# PIC32MZ0512EFF144 device description
Architecture: 32xxxx; Family: PIC32MZEF; Series: PIC32MZ
Registers are 32-bit, read-write, no defined reset value unless marked. A register's access mark holds for its fields unless they carry their own. Offsets are from the block's base; [hi:lo] are bit positions; {n}, {i} and the like mark numbered series.

## NVM
Instances: NVM 0x1f800600 in periph_pb1_std
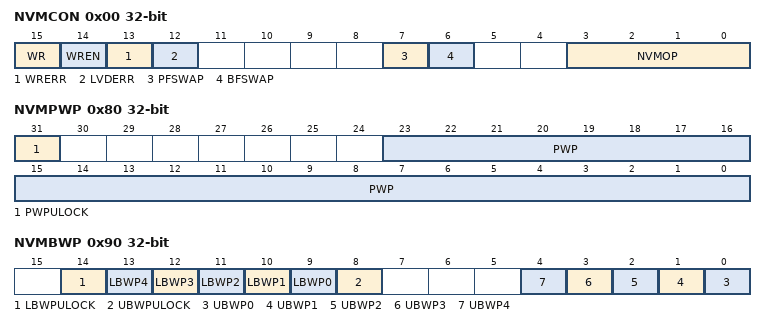
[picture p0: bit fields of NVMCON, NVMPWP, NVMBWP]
0x00 NVMCON — Flash Programming Control Register
  [15] WR — Write Control bit
    1=Initiate a Flash operation; 0=Flash operation is complete or inactive
  [14] WREN — Write Enable bit
    1=Enable writes to the WR bit and disables writes to the NVMOP bits; 0=Disable writes to WR bit and enables writes to the NVMOP bits
  [13] WRERR — Write Error bit
    1=Program or erase sequence did not complete successfully; 0=Program or erase sequence completed normally
  [12] LVDERR — Low-Voltage Detect Error bit
    1=Low-voltage detected (possible data corruption; 0=Voltage level is acceptable for programming
  [7] PFSWAP — Program Flash Bank Swap Control bit
    1=Program Flash Bank 2 is mapped to the lower mapped region and program Flash Bank 1 is mapped to the upper mapped region; 0=Program Flash Bank 1 is mapped to the lower mapped region and program Flash Bank 2 is mapped to the upper mapped region
  [6] BFSWAP — Boot Flash Bank Alias Swap Control bit
    1=Boot Flash Bank 2 is mapped to the lower boot alias and boot Flash Bank 1 is mapped to the upper boot alias; 0=Boot Flash Bank 1 is mapped to the lower boot alias and boot Flash Bank 2 is mapped to the upper boot alias
  [3:0] NVMOP — NVM Operation bits
    3=Program erase operation: erase all of program Flash memory (all pages must be unprotected; 6=Upper program Flash memory erase operation: erases only the upper mapped region of program Flash (all pages in that region must be unprotected); 5=Lower program Flash memory erase operation: erases only the lower mapped region of program Flash (all pages in that region must be unprotected); 4=Page erase operation: erases page selected by NVMADDR; 3=Row program operation: programs row selected by NVMADDR; 2=Quad Word (128-bit) program operation: programs the 128-bit Flash word selected by NVMADDR; 1=Word program operation: programs word selected by NVMADDR; 0=No operation
0x10 NVMKEY wo — Programming Unlock Register
0x20 NVMADDR — Flash Address Register
{0x30+0x10*i} NVMDATA{i} (i=0..3) — Flash Data Register (x = 0-3
0x70 NVMSRCADDR — Source Data Address Register
0x80 NVMPWP — Program Flash Write-Protect Register
  [31] PWPULOCK — Program Flash Memory Page Write-protect Unlock bit
    1=Register is not locked and can be modified; 0=Register is locked and cannot be modified
  [23:0] PWP
0x90 NVMBWP — Flash Boot (Page) Write-Protect Register
  [14] LBWPULOCK — Lower Boot Alias Write-protect Unlock bit
    2=LBWPx bits are not locked and can be modified; 0=LBWPx bits are locked and cannot be modified
  [n+9] LBWP{n} (n=0..4) — Lower Boot Alias Page {n} Write-protect bit
    0=Write protection for physical address {0x1FC00000+0x4000*n} through {0x1FC03FFF+0x4000*n} enabled; 0=Write protection for physical address {0x1FC00000+0x4000*n} through {0x1FC03FFF+0x4000*n} disabled
  [8] UBWPULOCK — Upper Boot Alias Write-protect Unlock bit
    0=UBWPx bits are not locked and can be modified; 0=UBWPx bits are locked and cannot be modified
  [n] UBWP{n} (n=0..4) — Upper Boot Alias Page {n} Write-protect bit
    1=Write protection for physical address {0x1FC20000+0x4000*n} through {0x1FC23FFF+0x4000*n} enabled; 0=Write protection for physical address {0x1FC20000+0x4000*n} through {0x1FC23FFF+0x4000*n} disabled
0xA0 NVMCON2 — Flash Programming Control Register 2
  [7:6] SWAPLOCK — Flash Memory Swap Lock Control bits
    3=PFSWAP and BFSWAP are not writable and SWAPLOCK is not writable; 2=PFSWAP and BFSWAP are not writable and SWAPLOCK is writable; 1=PFSWAP and BFSWAP are not writable and SWAPLOCK is writable; 0=PFSWAP and BFSWAP are writable and SWAPLOCK is writable
